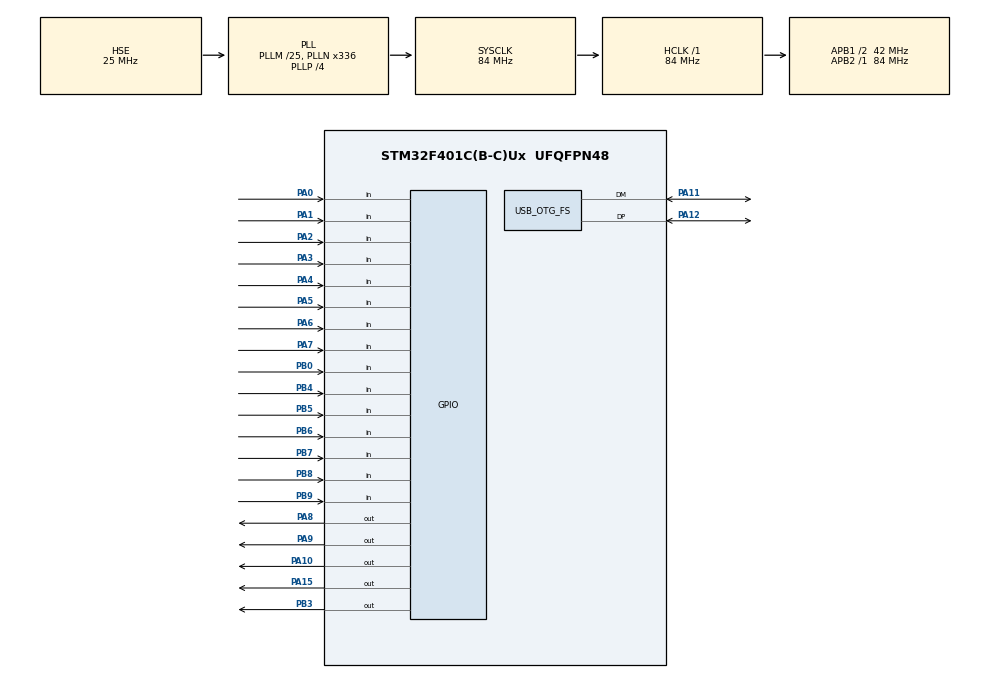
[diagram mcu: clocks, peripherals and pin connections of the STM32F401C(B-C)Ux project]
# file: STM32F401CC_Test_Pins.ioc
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Mcu.Family=STM32F4
Mcu.Name=STM32F401C(B-C)Ux
Mcu.Package=UFQFPN48
NVIC.OTG_FS_IRQn=true\:0\:0\:false\:false\:true\:false\:true
NVIC.PriorityGroup=NVIC_PRIORITYGROUP_4
NVIC.TIM3_IRQn=true\:0\:0\:false\:false\:true\:true\:true
PA0-WKUP.GPIO_Mode=GPIO_MODE_INPUT
PA0-WKUP.GPIO_PuPd=GPIO_PULLUP
PA0-WKUP.Signal=GPIO_Input
PA1.GPIO_Mode=GPIO_MODE_INPUT
PA1.GPIO_PuPd=GPIO_PULLUP
PA1.Signal=GPIO_Input
PA10.GPIO_ModeDefaultOutputPP=GPIO_MODE_OUTPUT_PP
PA10.GPIO_PuPd=GPIO_NOPULL
PA10.GPIO_Speed=GPIO_SPEED_FREQ_VERY_HIGH
PA10.PinState=GPIO_PIN_SET
PA10.Signal=GPIO_Output
PA11.Mode=Device_Only
PA11.Signal=USB_OTG_FS_DM
PA12.Mode=Device_Only
PA12.Signal=USB_OTG_FS_DP
PA13.Mode=Serial_Wire
PA13.Signal=SYS_JTMS-SWDIO
PA14.Mode=Serial_Wire
PA14.Signal=SYS_JTCK-SWCLK
PA15.GPIO_ModeDefaultOutputPP=GPIO_MODE_OUTPUT_PP
PA15.GPIO_PuPd=GPIO_NOPULL
PA15.GPIO_Speed=GPIO_SPEED_FREQ_VERY_HIGH
PA15.PinState=GPIO_PIN_SET
PA15.Signal=GPIO_Output
PA2.GPIO_Mode=GPIO_MODE_INPUT
PA2.GPIO_PuPd=GPIO_PULLUP
PA2.Signal=GPIO_Input
PA3.GPIO_Mode=GPIO_MODE_INPUT
PA3.GPIO_PuPd=GPIO_PULLUP
PA3.Signal=GPIO_Input
PA4.GPIO_Mode=GPIO_MODE_INPUT
PA4.GPIO_PuPd=GPIO_PULLUP
PA4.Signal=GPIO_Input
PA5.GPIO_Mode=GPIO_MODE_INPUT
PA5.GPIO_PuPd=GPIO_PULLUP
PA5.Signal=GPIO_Input
PA6.GPIO_Mode=GPIO_MODE_INPUT
PA6.GPIO_PuPd=GPIO_PULLUP
PA6.Signal=GPIO_Input
PA7.GPIO_Mode=GPIO_MODE_INPUT
PA7.GPIO_PuPd=GPIO_PULLUP
PA7.Signal=GPIO_Input
PA8.GPIO_ModeDefaultOutputPP=GPIO_MODE_OUTPUT_PP
PA8.GPIO_PuPd=GPIO_NOPULL
PA8.GPIO_Speed=GPIO_SPEED_FREQ_VERY_HIGH
PA8.PinState=GPIO_PIN_SET
PA8.Signal=GPIO_Output
PA9.GPIO_ModeDefaultOutputPP=GPIO_MODE_OUTPUT_PP
PA9.GPIO_PuPd=GPIO_NOPULL
PA9.GPIO_Speed=GPIO_SPEED_FREQ_VERY_HIGH
PA9.PinState=GPIO_PIN_SET
PA9.Signal=GPIO_Output
PB0.GPIO_Mode=GPIO_MODE_INPUT
PB0.GPIO_PuPd=GPIO_PULLUP
PB0.Signal=GPIO_Input
PB3.GPIO_ModeDefaultOutputPP=GPIO_MODE_OUTPUT_PP
PB3.GPIO_PuPd=GPIO_NOPULL
PB3.GPIO_Speed=GPIO_SPEED_FREQ_VERY_HIGH
PB3.PinState=GPIO_PIN_SET
PB3.Signal=GPIO_Output
PB4.GPIO_Mode=GPIO_MODE_INPUT
PB4.GPIO_PuPd=GPIO_PULLUP
PB4.Signal=GPIO_Input
PB5.GPIO_Mode=GPIO_MODE_INPUT
PB5.GPIO_PuPd=GPIO_PULLUP
PB5.Signal=GPIO_Input
PB6.GPIO_Mode=GPIO_MODE_INPUT
PB6.GPIO_PuPd=GPIO_PULLUP
PB6.Signal=GPIO_Input
PB7.GPIO_Mode=GPIO_MODE_INPUT
PB7.GPIO_PuPd=GPIO_PULLUP
PB7.Signal=GPIO_Input
PB8.GPIO_Mode=GPIO_MODE_INPUT
PB8.GPIO_PuPd=GPIO_PULLUP
PB8.Signal=GPIO_Input
PB9.GPIO_Mode=GPIO_MODE_INPUT
PB9.GPIO_PuPd=GPIO_PULLUP
PB9.Signal=GPIO_Input
PH0\ -\ OSC_IN.Mode=HSE-External-Oscillator
PH0\ -\ OSC_IN.Signal=RCC_OSC_IN
PH1\ -\ OSC_OUT.Mode=HSE-External-Oscillator
PH1\ -\ OSC_OUT.Signal=RCC_OSC_OUT
ProjectManager.HeapSize=0x200
ProjectManager.StackSize=0x400
ProjectManager.TargetToolchain=Makefile
RCC.48MHZClocksFreq_Value=48000000
RCC.AHBFreq_Value=84000000
RCC.APB1CLKDivider=RCC_HCLK_DIV2
RCC.APB1Freq_Value=42000000
RCC.APB1TimFreq_Value=84000000
RCC.APB2Freq_Value=84000000
RCC.APB2TimFreq_Value=84000000
RCC.CortexFreq_Value=84000000
RCC.HCLKFreq_Value=84000000
RCC.HSE_VALUE=25000000
RCC.HSI_VALUE=16000000
RCC.LSE_VALUE=32768
RCC.PLLM=25
RCC.PLLN=336
RCC.PLLP=RCC_PLLP_DIV4
RCC.PLLQ=7
RCC.SYSCLKFreq_VALUE=84000000
RCC.SYSCLKSource=RCC_SYSCLKSOURCE_PLLCLK
RCC.VCOOutputFreq_Value=336000000
TIM3.Period=(1000000 / 1000) - 1
TIM3.Prescaler=(84000000 / 1000000) - 1
USB_DEVICE.CLASS_NAME_FS=HID
USB_DEVICE.HID_FS_BINTERVAL=0x01
USB_DEVICE.VirtualMode=Hid
USB_DEVICE.VirtualModeFS=Hid_FS
USB_OTG_FS.VirtualMode=Device_Only
VP_TIM3_VS_ClockSourceINT.Mode=Internal
VP_USB_DEVICE_VS_USB_DEVICE_HID_FS.Mode=HID_FS
board=custom

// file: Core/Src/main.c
/* USER CODE BEGIN Header */
/**
 ******************************************************************************
 * @file           : main.c
 * @brief          : Main program body
 ******************************************************************************
 * @attention
 *
 * <h2><center>&copy; Copyright (c) 2022 STMicroelectronics.
 * All rights reserved.</center></h2>
 *
 * This software component is licensed by ST under Ultimate Liberty license
 * SLA0044, the "License"; You may not use this file except in compliance with
 * the License. You may obtain a copy of the License at:
 *                             www.st.com/SLA0044
 *
 ******************************************************************************
 */
/* USER CODE END Header */
#include "main.h"
#include "usb_device.h"

/* USER CODE BEGIN Includes */
#include "text.h"
#include "GPIO_Config.h"
#include "keyboard_map.h"
#include "string.h"
#include "stdlib.h"
// #include "keyboard_map.h"
/* USER CODE END Includes */

TIM_HandleTypeDef htim3;

void SystemClock_Config(void);
static void MX_GPIO_Init(void);
static void MX_TIM3_Init(void);

/* USER CODE BEGIN 0 */

#define TIMEOUT_MS 20

extern USBD_HandleTypeDef hUsbDeviceFS;

#define USBD_Keyboard_State() (((volatile USBD_HID_HandleTypeDef*)hUsbDeviceFS.pClassData)->state)

#define COLS 15U
#define ROWS 5U

PinId_t* colPins[COLS] = {
    PA0, PA1, PA2, PA3, PA4,
    PA5, PA6, PA7, PB0, PB9,
    PB8, PB15, PB14, PB5, PB4
};

PinId_t* rowPins[ROWS] = {
    PA8,
    PA9,
    PA10,
    PA15,
    PB3,
};

#define HID_NORMAL_ID 1U
#define HID_MEDIA_ID 2U
#define FN_KEY 70U

KeyboardHID_t myHID = {HID_NORMAL_ID};
MediaHID_t myMedia  = {HID_MEDIA_ID};
uint16_t Pressed[ROWS*COLS] = {0};
uint16_t TimeOut[ROWS*COLS] = {0};

void keyboardService()
{
    static int update = 0;
    static int alternate = 0;
    static int shit = 0;
    static int clean = 0;
    static uint8_t shitActivate = 0;
    static int textPos = 0;
    static int npressed = 0;

    // scan matrix
    for(int i = 0; i < ROWS; i++)
    {
        PinId_Write(rowPins[i], 0);
        volatile uint32_t j = 0;
        for(; j < 10; j++)
            ;
        for(j = 0; j < COLS; j++)
        {
            uint32_t pos = i * 15 + j;
            int col_pressed = !PinId_Read(colPins[j]);

            // set/unset alternate mode
            if(pos == FN_KEY) { alternate = col_pressed; continue; }

            if(col_pressed)
            {
                // shit mode toggle on press (press and release alt key and column 14 of each row simultaneously)
                if(j == 14)
                {
                    shitActivate |= (1U << i);
                    if((shitActivate == 0x1f) && (alternate == 1))
                    {
                        if(shit == 0U) shit = 2U;
                        else if(shit == 3U) shit = 1U;
                    }
                }

                // if alternate mode is on and alternate key is defined
                uint16_t key = (alternate && keys_alternate[pos] != 0)? keys_alternate[pos] : keys[pos];

                // press key
                // if key of 'pos' is free and not in debounce timeout
                if(Pressed[pos] == 0 && TimeOut[pos] == 0)
                {
                    if(USBD_Keyboard_press(&myHID, &myMedia, key) == key)
                    {
                        update |= ((key & KEY_TYPE_MASK) == KEY_TYPE_MEDIA)? 8U : 4U; // update HID Type
                        update |= 1U;   // update pressed flag
                        Pressed[pos] = key; // assign key to pressed array
                        npressed++;
                    }
                }
            }
            else
            {
                // shit mode toggle on release (press and release alt key and column 14 of each row simultaneously)
                if(j == 14)
                {
                    shitActivate &= ~(1U << i);
                    if(shitActivate == 0)
                    {
                        int prevShit = shit;
                        if(shit == 2U) shit = 3U;
                        else if(shit == 1U) shit = 0U;
                        if(prevShit != shit)
                            {clean = 1; textPos = 0;}
                    }
                }

                // decrement key timer
                TimeOut[pos] = TimeOut[pos] > 0? (TimeOut[pos] - 1) : 0;

                // release key
                if(Pressed[pos] != 0)
                {
                    if(USBD_Keyboard_release(&myHID, &myMedia, Pressed[pos]) == Pressed[pos])
                    {
                        // update HID Type
                        update |= ((Pressed[pos] & KEY_TYPE_MASK) == KEY_TYPE_MEDIA)? 8U : 4U;
                        update |= 2U; // update release flag
                        Pressed[pos] = 0; // unassign key from pressed array
                        TimeOut[pos] = TIMEOUT_MS; // set debounce timeout
                        npressed--;
                    }
                }
            }
        }
        PinId_Write(rowPins[i], 1);
    }
    static uint32_t shitTimer = 0;
    if (shit == 3)
    {
        if ((HAL_GetTick() - shitTimer >= 500) && npressed > 0)
        {
            update |= 1U;
            shitTimer = HAL_GetTick() - (500);
        }
        else if (npressed == 0)
            shitTimer = HAL_GetTick();
    }

    // send report
    if (update & 3U)
    {
        if(clean)
        {
            uint8_t tmp[9] = {HID_NORMAL_ID, 0, 0, 0, 0, 0, 0, 0, 0};
            uint8_t tmp1[3] = {HID_MEDIA_ID, 0, 0};
            USBD_HID_SendReport(&hUsbDeviceFS, (uint8_t*)tmp, 9);
            while(USBD_Keyboard_State() != HID_IDLE)
                    ;
            USBD_HID_SendReport(&hUsbDeviceFS, (uint8_t*)tmp1, 3);
            while(USBD_Keyboard_State() != HID_IDLE)
                    ;
            clean = 0;
        }
        if(((update & 1U) == 1U) && shit == 3) // shit mode
        {
            // new HID instance
            KeyboardHID_t shitHID = {HID_NORMAL_ID, 0, 0, {0, 0, 0, 0, 0, 0}};
            MediaHID_t shitMedia = {HID_MEDIA_ID, {0, 0}};
            // press
            USBD_Keyboard_press(&shitHID, &shitMedia, txt[textPos]);
            USBD_HID_SendReport(&hUsbDeviceFS, (uint8_t*)&shitHID, sizeof(shitHID));
            while(USBD_Keyboard_State() != HID_IDLE)
                    ;
            // release
            USBD_Keyboard_releaseAll(&shitHID, &shitMedia);
            USBD_HID_SendReport(&hUsbDeviceFS, (uint8_t*)&shitHID, sizeof(shitHID));
            while(USBD_Keyboard_State() != HID_IDLE)
                    ;
            textPos = (textPos + 1) % size_txt;
        }
        else if (shit == 0)
        {
            if(update & 8U) // media key
            {
                myMedia.ID = HID_MEDIA_ID;
                USBD_HID_SendReport(&hUsbDeviceFS, (uint8_t*)&myMedia, sizeof(myMedia));
                while(USBD_Keyboard_State() != HID_IDLE)
                        ;
            }
            if(update & 4U) // normal key
            {
                myHID.ID = HID_NORMAL_ID;
                USBD_HID_SendReport(&hUsbDeviceFS, (uint8_t*)&myHID, sizeof(myHID));
                while(USBD_Keyboard_State() != HID_IDLE)
                        ;
            }
        }
        update = 0;
    }
}

volatile uint32_t LED_toggle = 0U;

void __attribute__((optimize("-O0"))) HAL_TIM_PeriodElapsedCallback(TIM_HandleTypeDef* htim)
{

    if(htim == &htim3)
        GPIOC->ODR ^= (LED_toggle << 13U);
    // NVIC_DisableIRQ(TIM3_IRQn);
    // keyboardService();
    // NVIC_EnableIRQ(TIM3_IRQn);
}

/* USER CODE END 0 */

int __attribute__((optimize("-O0"))) main(void)
{

    /* MCU Configuration--------------------------------------------------------*/

    /* Reset of all peripherals, Initializes the Flash interface and the Systick. */
    HAL_Init();

    /* Configure the system clock */
    SystemClock_Config();

    /* USER CODE BEGIN SysInit */

    NVIC_SetPriority(OTG_FS_IRQn, 6);
    NVIC_SetPriority(TIM3_IRQn, 67);
    /* USER CODE END SysInit */

    /* Initialize all configured peripherals */
    MX_GPIO_Init();
    MX_TIM3_Init();
    MX_USB_DEVICE_Init();
    /* USER CODE BEGIN 2 */
    TIM3->PSC = (84000000 / 10000) - 1;
    TIM3->ARR = (10000 / 1) - 1;
    NVIC_SetPriority(OTG_FS_IRQn, 6);
    NVIC_SetPriority(TIM3_IRQn, 67);
    HAL_TIM_Base_Start_IT(&htim3);

    while(USBD_Keyboard_State() != HID_IDLE)
        ;
    LED_toggle = 1U;

    /* USER CODE END 2 */

    /* Infinite loop */
    while (1)
    {

        /* USER CODE BEGIN 3 */
        keyboardService();
        HAL_Delay(0);
    }
    /* USER CODE END 3 */
}

void SystemClock_Config(void)
{
    RCC_OscInitTypeDef RCC_OscInitStruct = {0};
    RCC_ClkInitTypeDef RCC_ClkInitStruct = {0};

    /** Configure the main internal regulator output voltage
     */
    __HAL_RCC_PWR_CLK_ENABLE();
    __HAL_PWR_VOLTAGESCALING_CONFIG(PWR_REGULATOR_VOLTAGE_SCALE2);
    /** Initializes the RCC Oscillators according to the specified parameters
     * in the RCC_OscInitTypeDef structure.
     */
    RCC_OscInitStruct.OscillatorType = RCC_OSCILLATORTYPE_HSE;
    RCC_OscInitStruct.HSEState = RCC_HSE_ON;
    RCC_OscInitStruct.PLL.PLLState = RCC_PLL_ON;
    RCC_OscInitStruct.PLL.PLLSource = RCC_PLLSOURCE_HSE;
    RCC_OscInitStruct.PLL.PLLM = 25;
    RCC_OscInitStruct.PLL.PLLN = 336;
    RCC_OscInitStruct.PLL.PLLP = RCC_PLLP_DIV4;
    RCC_OscInitStruct.PLL.PLLQ = 7;
    if (HAL_RCC_OscConfig(&RCC_OscInitStruct) != HAL_OK)
    {
        Error_Handler();
    }
    /** Initializes the CPU, AHB and APB buses clocks
     */
    RCC_ClkInitStruct.ClockType = RCC_CLOCKTYPE_HCLK | RCC_CLOCKTYPE_SYSCLK | RCC_CLOCKTYPE_PCLK1 | RCC_CLOCKTYPE_PCLK2;
    RCC_ClkInitStruct.SYSCLKSource = RCC_SYSCLKSOURCE_PLLCLK;
    RCC_ClkInitStruct.AHBCLKDivider = RCC_SYSCLK_DIV1;
    RCC_ClkInitStruct.APB1CLKDivider = RCC_HCLK_DIV2;
    RCC_ClkInitStruct.APB2CLKDivider = RCC_HCLK_DIV1;

    if (HAL_RCC_ClockConfig(&RCC_ClkInitStruct, FLASH_LATENCY_2) != HAL_OK)
    {
        Error_Handler();
    }
}

static void MX_TIM3_Init(void)
{

    TIM_ClockConfigTypeDef sClockSourceConfig = {0};
    TIM_MasterConfigTypeDef sMasterConfig = {0};

    htim3.Instance = TIM3;
    htim3.Init.Prescaler = (84000000 / 1000000) - 1;
    htim3.Init.CounterMode = TIM_COUNTERMODE_UP;
    htim3.Init.Period = (1000000 / 1000) - 1;
    htim3.Init.ClockDivision = TIM_CLOCKDIVISION_DIV1;
    htim3.Init.AutoReloadPreload = TIM_AUTORELOAD_PRELOAD_DISABLE;
    if (HAL_TIM_Base_Init(&htim3) != HAL_OK)
    {
        Error_Handler();
    }
    sClockSourceConfig.ClockSource = TIM_CLOCKSOURCE_INTERNAL;
    if (HAL_TIM_ConfigClockSource(&htim3, &sClockSourceConfig) != HAL_OK)
    {
        Error_Handler();
    }
    sMasterConfig.MasterOutputTrigger = TIM_TRGO_RESET;
    sMasterConfig.MasterSlaveMode = TIM_MASTERSLAVEMODE_DISABLE;
    if (HAL_TIMEx_MasterConfigSynchronization(&htim3, &sMasterConfig) != HAL_OK)
    {
        Error_Handler();
    }
}

static void MX_GPIO_Init(void)
{
    GPIO_InitTypeDef GPIO_InitStruct = {0};

    /* GPIO Ports Clock Enable */
    __HAL_RCC_GPIOH_CLK_ENABLE();
    __HAL_RCC_GPIOA_CLK_ENABLE();
    __HAL_RCC_GPIOB_CLK_ENABLE();
    __HAL_RCC_GPIOC_CLK_ENABLE();

    /*Configure GPIO pin Output Level */
    HAL_GPIO_WritePin(GPIOA, GPIO_PIN_8 | GPIO_PIN_9 | GPIO_PIN_10 | GPIO_PIN_15, GPIO_PIN_SET);

    /*Configure GPIO pin Output Level */
    HAL_GPIO_WritePin(GPIOB, GPIO_PIN_3, GPIO_PIN_SET);

    /*Configure GPIO pins : PA0 PA1 PA2 PA3
                             PA4 PA5 PA6 PA7 */
    GPIO_InitStruct.Pin = GPIO_PIN_0 | GPIO_PIN_1 | GPIO_PIN_2 | GPIO_PIN_3 | GPIO_PIN_4 | GPIO_PIN_5 | GPIO_PIN_6 | GPIO_PIN_7;
    GPIO_InitStruct.Mode = GPIO_MODE_INPUT;
    GPIO_InitStruct.Pull = GPIO_PULLUP;
    HAL_GPIO_Init(GPIOA, &GPIO_InitStruct);

    /*Configure GPIO pins : PB0 PB4 PB5 PB6
                             PB7 PB8 PB9 */
    GPIO_InitStruct.Pin = GPIO_PIN_0 | GPIO_PIN_4 | GPIO_PIN_5 | GPIO_PIN_6 | GPIO_PIN_7 | GPIO_PIN_8 | GPIO_PIN_9;
    GPIO_InitStruct.Mode = GPIO_MODE_INPUT;
    GPIO_InitStruct.Pull = GPIO_PULLUP;
    HAL_GPIO_Init(GPIOB, &GPIO_InitStruct);

    /*Configure GPIO pins : PA8 PA9 PA10 PA15 */
    GPIO_InitStruct.Pin = GPIO_PIN_8 | GPIO_PIN_9 | GPIO_PIN_10 | GPIO_PIN_15;
    GPIO_InitStruct.Mode = GPIO_MODE_OUTPUT_PP;
    GPIO_InitStruct.Pull = GPIO_NOPULL;
    GPIO_InitStruct.Speed = GPIO_SPEED_FREQ_VERY_HIGH;
    HAL_GPIO_Init(GPIOA, &GPIO_InitStruct);

    /*Configure GPIO pin : PB3 */
    GPIO_InitStruct.Pin = GPIO_PIN_3;
    GPIO_InitStruct.Mode = GPIO_MODE_OUTPUT_PP;
    GPIO_InitStruct.Pull = GPIO_NOPULL;
    GPIO_InitStruct.Speed = GPIO_SPEED_FREQ_VERY_HIGH;
    HAL_GPIO_Init(GPIOB, &GPIO_InitStruct);

    /*Configure GPIO pin : PC13 */
    GPIO_InitStruct.Pin = GPIO_PIN_13;
    GPIO_InitStruct.Mode = GPIO_MODE_OUTPUT_PP;
    GPIO_InitStruct.Pull = GPIO_NOPULL;
    GPIO_InitStruct.Speed = GPIO_SPEED_FREQ_LOW;
    HAL_GPIO_Init(GPIOC, &GPIO_InitStruct);
}

void Error_Handler(void)
{
    __disable_irq();
    while (1)
    {
    }
}

/************************ (C) COPYRIGHT STMicroelectronics *****END OF FILE****/
